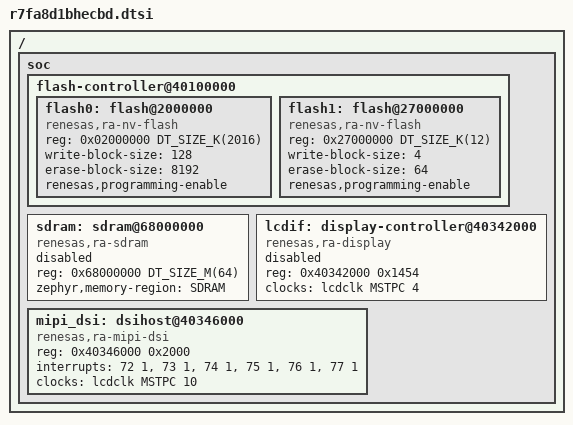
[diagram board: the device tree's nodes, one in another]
/*
 * Copyright (c) 2024 Renesas Electronics Corporation
 *
 * SPDX-License-Identifier: Apache-2.0
 */

#include <arm/renesas/ra/ra8/r7fa8d1xh.dtsi>
#include <zephyr/dt-bindings/mipi_dsi/mipi_dsi.h>

/ {
	soc {
		flash-controller@40100000 {
			flash0: flash@2000000 {
				compatible = "renesas,ra-nv-flash";
				reg = <0x02000000 DT_SIZE_K(2016)>;
				write-block-size = <128>;
				erase-block-size = <8192>;
				renesas,programming-enable;
			};

			flash1: flash@27000000 {
				compatible = "renesas,ra-nv-flash";
				reg = <0x27000000 DT_SIZE_K(12)>;
				write-block-size = <4>;
				erase-block-size = <64>;
				renesas,programming-enable;
			};
		};

		sdram: sdram@68000000 {
			compatible = "renesas,ra-sdram", "zephyr,memory-region";
			reg = <0x68000000 DT_SIZE_M(64)>; /* 512 Mbits */
			zephyr,memory-region = "SDRAM";
			status = "disabled";
		};

		lcdif: display-controller@40342000 {
			compatible = "renesas,ra-display";
			reg = <0x40342000 0x1454>;
			clocks = <&lcdclk MSTPC 4>;
			status = "disabled";
		};

		mipi_dsi: dsihost@40346000 {
			compatible = "renesas,ra-mipi-dsi";
			#address-cells = <1>;
			#size-cells = <0>;
			reg = <0x40346000 0x2000>;
			interrupts = <72 1>, <73 1>, <74 1>, <75 1>, <76 1>, <77 1>;
			interrupt-names = "sq0", "sq1", "vm", "rcv", "ferr", "ppi";
			clocks = <&lcdclk MSTPC 10>;
			status = "okay";
		};
	};
};
